# MEC1322 register map
Vendor: Microchip Technology Inc.; Series: ARMCM4F; File version: 1.0
CPU: CM4 r1p0, little endian, MPU, FPU, 3 interrupt priority bits
Registers are 32-bit, read-write, reset 0x0 unless marked. A register's access mark holds for its fields unless they carry their own. Offsets are from the block's base; [hi:lo] are bit positions; lines under a group give offsets from that group; {n}, {i} and the like mark numbered series.

## DMA — The Internal DMA Controller transfers data to/from the source from/to the destination. The firmware is responsible for setting up each channel. Afterwards either the firmware or the hardware may perform the flow control. The hardware flow control exists entirely inside the source device. Each transfer may be 1, 2, or 4 bytes in size, so long as the device supports a transfer of that size. Every device must be on the internal 32-bit address space.
Base 0x40002400
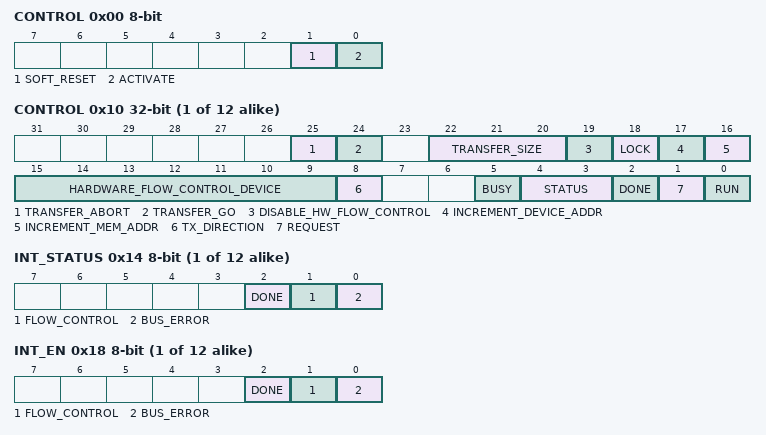
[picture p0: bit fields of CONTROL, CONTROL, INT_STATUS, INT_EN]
0x00 CONTROL 8-bit — Soft reset the entire module. Enable the blocks operation.
  [1] SOFT_RESET write — Soft reset the entire module. This bit is self-clearing.
  [0] ACTIVATE — Enable the blocks operation. (R/WS). 1=Enable block. Each individual channel must be enabled separately. 0=Disable all channels.
0x04 DATA_PACKET read — Debug register that has the data that is stored in the Data Packet. This data is read data from the currently active transfer source.
{0x10+0x20*i} CH[{i}] (i=0..11) group — Channel implemented will have these registers to determine that channel's operation.
  0x00 ACTIVATE 8-bit — Enable this channel for operation. The DMA Main Control: Activate must also be enabled for this channel to be operational.
    [0] EN — Enable this channel for operation. 1=Enable channel(block). Each individual channel must be enabled separately. 0=Disable channel(block).
  0x04 MEM_START_ADDR — This is the starting address for the Memory device.
  0x08 MEM_END_ADDR — This is the ending address for the Memory device.
  0x0C DEVICE_ADDR — This is the Master Device address.
  0x10 CONTROL — DMA Channel N Control
    [25] TRANSFER_ABORT — This is used to abort the current transfer on this DMA Channel. The aborted transfer will be forced to terminate immediately.
    [24] TRANSFER_GO — This is used for the Firmware Flow Control DMA transfer.
    [22:20] TRANSFER_SIZE — This is the transfer size in Bytes of each Data Packet transfer. Note: The transfer size must be a legal AMBA transfer size. Valid sizes are 1, 2 and 4 Bytes.
    [19] DISABLE_HW_FLOW_CONTROL — This will Disable the Hardware Flow Control. When disabled, any DMA Master device attempting to communicate to the DMA over the DMA Flow Control Interface (Ports: dma_req, dma_term, and dma_done) will be ignored. This should be set before using the DMA channel in Firmware Flow Control mode.
    [18] LOCK — This is used to lock the arbitration of the Channel Arbiter on this channel once this channel is granted. Once this is locked, it will remain on the arbiter until it has completed it transfer (either the Transfer Aborted, Transfer Done or Transfer Terminated conditions).
    [17] INCREMENT_DEVICE_ADDR — This will enable an auto-increment to the DMA Channel Device Address. 1: Increment the DMA Channel Device Address by DMA Channel Control:Transfer Size after every Data Packet transfer. 0: Do nothing
    [16] INCREMENT_MEM_ADDR — This will enable an auto-increment to the DMA Channel Memory Address. 1=Increment the DMA Channel Memory Address by DMA Channel Control:Transfer Size after every Data Packet transfer. 0=Do nothing
    [15:9] HARDWARE_FLOW_CONTROL_DEVICE — This is the device that is connected to this channel as its Hardware Flow Control master. The Flow Control Interface is a bus with each master concatenated onto it. This selects which bus index of the concatenated Flow Control Interface bus is targeted towards this channel. The Flow Control Interface Port list is dma_req, dma_term, and dma_done.
    [8] TX_DIRECTION — This determines the direction of the DMA Transfer. 1=Data Packet Read from Memory Start Address followed by Data Packet Write to Device Address. 0=Data Packet Read from Device Address followed by Data Packet Write to Memory Start Address
    [5] BUSY — This is a status signal. 1=The DMA Channel is busy (FSM is not IDLE). 0=The DMA Channel is not busy (FSM is IDLE)
    [4:3] STATUS — This is a status signal. The status decode is listed in priority order with the highest priority first. 3: Error detected by the DMA. 2: The DMA Channel is externally done, in that the Device has terminated the transfer over the Hardware Flow Control through the Port dma_term. 1: The DMA Channel is locally done, in that Memory Start Address equals Memory End Address. 0: DMA Channel Control:Run is Disabled (0x0)
    [2] DONE — This is a status signal. It is only valid while DMA Channel Control: Run is Enabled. This is the inverse of the DMA Channel Control: Busy field, except this is qualified with the DMA Channel Control:Run field. 1=Channel is done. 0=Channel is not done or it is OFF
    [1] REQUEST — This is a status field. 1= There is a transfer request from the Master Device. 0= There is no transfer request from the Master Device
    [0] RUN — This is a control field. Note: This bit only applies to Hardware Flow Control mode. 1= This channel is enabled and will service transfer requests. 0=This channel is disabled. All transfer requests are ignored.
  0x14 INT_STATUS 8-bit — DMA Channel N Interrupt Status
    [2] DONE — This is an interrupt source register. This flags when the DMA Channel has completed a transfer successfully on its side. A completed transfer is defined as when the DMA Channel reaches its limit; Memory Start Address equals Memory End Address. A completion due to a Hardware Flow Control Terminate will not flag this interrupt. 1=Memory Start Address equals Memory End Address. 0=Memory Start Address does not equal Memory End Address
    [1] FLOW_CONTROL — This is an interrupt source register. This flags when the DMA Channel has encountered a Hardware Flow Control Request after the DMA Channel has completed the transfer. This means the Master Device is attempting to overflow the DMA. 1=Hardware Flow Control is requesting after the transfer has completed. 0=No Hardware Flow Control event
    [0] BUS_ERROR — This is an interrupt source register. This flags when there is an Error detected over the internal 32-bit AMBA Bus. 1: AMBA Error detected. (R/WC)
  0x18 INT_EN 8-bit — DMA CHANNEL N INTERRUPT ENABLE
    [2] DONE — This is an interrupt enable for DMA Channel Interrupt:Status Done. 1=Enable Interrupt. 0=Disable Interrupt
    [1] FLOW_CONTROL — This is an interrupt enable for DMA Channel Interrupt:Status Flow Control Error. 1=Enable Interrupt. 0=Disable Interrupt
    [0] BUS_ERROR — This is an interrupt enable for DMA Channel Interrupt:Status AMBA Bus Error. 1=Enable Interrupt. 0=Disable Interrupt
